# MCU_MCAN0_CFG register map
Vendor: Texas Instruments
Peripheral module from a debugger description file (folder J721S2).
Registers are 32-bit, access not given, reset 0x0 unless marked. A register's access mark holds for its fields unless they carry their own. Offsets are as the file gives them; lines under a group give offsets from that group; [hi:lo] are bit positions; {n}, {i} and the like mark numbered series; 'fields as' and 'values as' point back to an identical list; <NAME> marks a mode.

## MCU_MCAN0_CFG
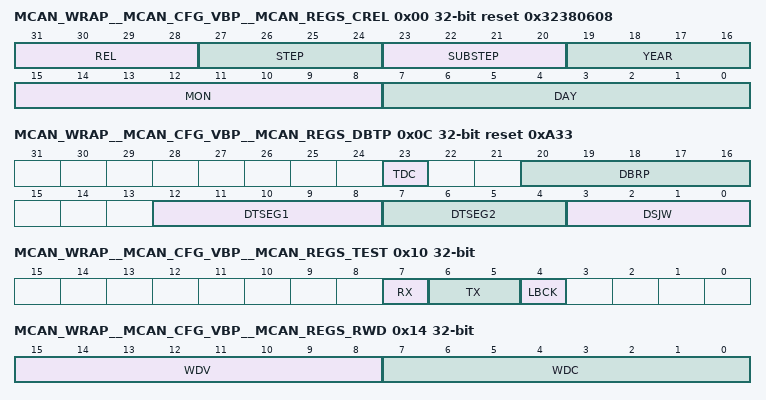
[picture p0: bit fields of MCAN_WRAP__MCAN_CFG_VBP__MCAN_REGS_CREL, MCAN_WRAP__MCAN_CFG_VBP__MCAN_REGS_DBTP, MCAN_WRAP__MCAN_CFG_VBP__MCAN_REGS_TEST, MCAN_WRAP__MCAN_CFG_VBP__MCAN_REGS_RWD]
0x00 MCAN_WRAP__MCAN_CFG_VBP__MCAN_REGS_CREL ro reset 0x32380608 — Release dependent constant (version + date)
  [31:28] REL — Core Release
  [27:24] STEP — Step of Core Release
  [23:20] SUBSTEP — Sub-Step of Core Release
  [19:16] YEAR — Time Stamp Year
  [15:8] MON — Time Stamp Month
  [7:0] DAY — Time Stamp Day
0x04 MCAN_WRAP__MCAN_CFG_VBP__MCAN_REGS_ENDN ro reset 0x87654321 — Constant 0x8765 4321
  [31:0] ETV — Endianess test value
0x08 MCAN_WRAP__MCAN_CFG_VBP__MCAN_REGS_CUST reset not defined — Optional customer-specific register
0x0C MCAN_WRAP__MCAN_CFG_VBP__MCAN_REGS_DBTP rw reset 0xA33 — Configuration of data phase bit timing, transmitter delay compensation enable
  [23] TDC — Transmitter Delay Compensation
  [20:16] DBRP — Data Baud Rate Prescaler
  [12:8] DTSEG1 — Data time segment before sample point
  [7:4] DTSEG2 — Data time segment after sample point
  [3:0] DSJW — Data resynchronization Jump Width
0x10 MCAN_WRAP__MCAN_CFG_VBP__MCAN_REGS_TEST access per field — Test mode selection
  [7] RX ro — Receive Pin
  [6:5] TX rw — Control of Transmit Pin
  [4] LBCK rw — Loop Back Mode
0x14 MCAN_WRAP__MCAN_CFG_VBP__MCAN_REGS_RWD access per field — Monitors the READY output of the Message RAM
  [15:8] WDV ro — Watchdog Value
  [7:0] WDC rw — Watchdog Counter Value
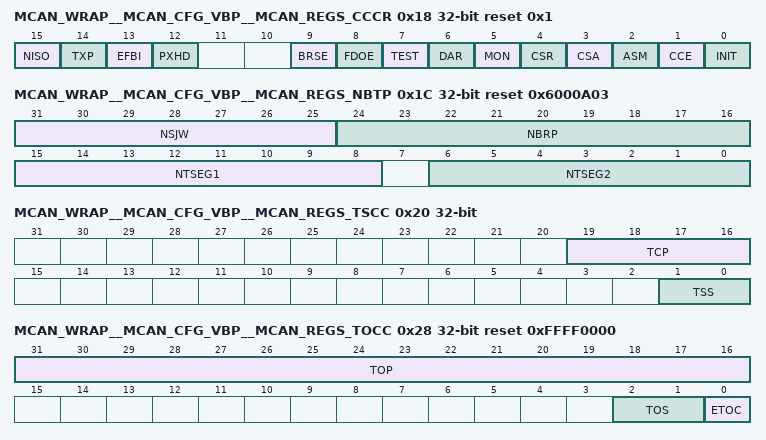
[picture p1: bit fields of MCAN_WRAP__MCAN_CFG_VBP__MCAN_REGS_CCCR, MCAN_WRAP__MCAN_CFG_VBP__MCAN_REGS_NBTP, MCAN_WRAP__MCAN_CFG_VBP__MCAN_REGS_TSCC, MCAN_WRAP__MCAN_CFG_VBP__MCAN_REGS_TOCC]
0x18 MCAN_WRAP__MCAN_CFG_VBP__MCAN_REGS_CCCR access per field reset 0x1 — Operation mode configuration
  [15] NISO rw — Non ISO Operation. 0= CAN FD frame format according to ISO 11898-1:2015. 1= CAN FD frame format according to Bosch CAN FD Specification 1.0
  [14] TXP rw — Transmit Pause
  [13] EFBI rw — Edge Filtering during Bus Integration
  [12] PXHD rw — Protocol Exception Handling Disable
  [9] BRSE rw — Bit Rate Switch Enable
  [8] FDOE rw — FD Operation Enable
  [7] TEST rw — Test Mode enable
  [6] DAR rw — Disable Automatic Retransmission
  [5] MON rw — Bus Monitoring Mode
  [4] CSR rw — Clock Stop Request
  [3] CSA ro — Clock Stop Acknowledge
  [2] ASM rw — Restricted Operation Mode
  [1] CCE rw — Configuration Change Enable
  [0] INIT rw — Initialization
0x1C MCAN_WRAP__MCAN_CFG_VBP__MCAN_REGS_NBTP rw reset 0x6000A03 — Configuration of arbitration phase bit timing
  [31:25] NSJW — Nominal Resynchronization Jump Width
  [24:16] NBRP — Nominal Baud Rate Prescaler
  [15:8] NTSEG1 — Nominal Time segment before sample point
  [6:0] NTSEG2 — Nominal Time segment after sample point
0x20 MCAN_WRAP__MCAN_CFG_VBP__MCAN_REGS_TSCC rw — Timestamp counter prescaler setting, selection of internal/external timestamp vector
  [19:16] TCP — Timestamp Counter Prescaler
  [1:0] TSS — Timestamp Select
0x24 MCAN_WRAP__MCAN_CFG_VBP__MCAN_REGS_TSCV — Read/reset timestamp counter
  [15:0] TSC — Timestamp Counter (access R/WTC)
0x28 MCAN_WRAP__MCAN_CFG_VBP__MCAN_REGS_TOCC rw reset 0xFFFF0000 — Configuration of timeout period, selection of timeout counter operation mode
  [31:16] TOP — Timeout Period
  [2:1] TOS — Timeout Select
  [0] ETOC — Enable Timeout Counter
0x2C MCAN_WRAP__MCAN_CFG_VBP__MCAN_REGS_TOCV reset 0xFFFF — Read/reset timeout counter
  [15:0] TOC — Timeout Counter (access R/WTC)
0x30 MCAN_WRAP__MCAN_CFG_VBP__MCAN_REGS_reserved00 reset not defined — Reserved field
0x34 MCAN_WRAP__MCAN_CFG_VBP__MCAN_REGS_reserved11 reset not defined — Reserved field
0x38 MCAN_WRAP__MCAN_CFG_VBP__MCAN_REGS_reserved22 reset not defined — Reserved field
0x3C MCAN_WRAP__MCAN_CFG_VBP__MCAN_REGS_reserved33 reset not defined — Reserved field
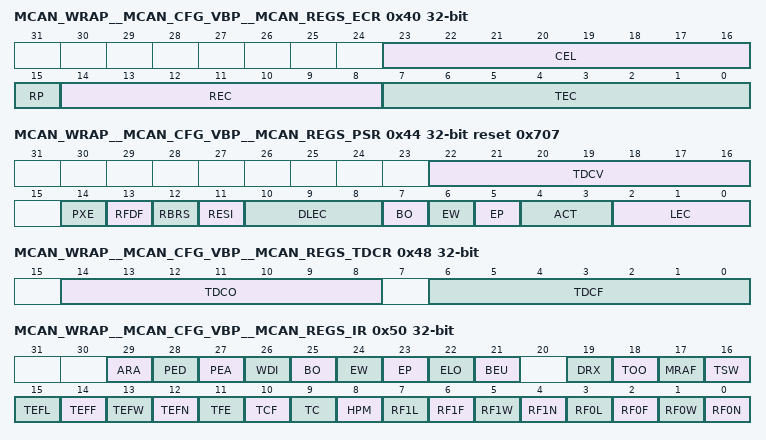
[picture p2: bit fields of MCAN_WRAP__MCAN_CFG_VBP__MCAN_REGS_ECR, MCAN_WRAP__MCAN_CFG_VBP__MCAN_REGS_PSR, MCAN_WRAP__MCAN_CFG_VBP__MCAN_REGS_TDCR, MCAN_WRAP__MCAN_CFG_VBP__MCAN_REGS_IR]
0x40 MCAN_WRAP__MCAN_CFG_VBP__MCAN_REGS_ECR ro — State of Rx/Tx Error Counter, CAN Error Logging
  [23:16] CEL — CAN Error Logging
  [15] RP — Receive Error Passive
  [14:8] REC — Receive Error Counter
  [7:0] TEC — Transmit Error Counter
0x44 MCAN_WRAP__MCAN_CFG_VBP__MCAN_REGS_PSR ro reset 0x707 — CAN protocol controller status, transmitter delay compensation value
  [22:16] TDCV — Transmitter Delay Compensation Value
  [14] PXE — Protocol Exception Event
  [13] RFDF — Received a CAN FD Message
  [12] RBRS — BRS flag of last received CAN FD Message
  [11] RESI — ESI flag of last received CAN FD Message
  [10:8] DLEC — Data Phase Last Error Code
  [7] BO — Bus_Off status
  [6] EW — Warning Status
  [5] EP — Error Passive
  [4:3] ACT — Activity
  [2:0] LEC — Last Error Code
0x48 MCAN_WRAP__MCAN_CFG_VBP__MCAN_REGS_TDCR rw — configuration of transmitter delay compensation offset and filter window length
  [14:8] TDCO — Transmitter Delay Compensation Offset
  [6:0] TDCF — Transmitter Delay Compensation Filter Window Length
0x4C MCAN_WRAP__MCAN_CFG_VBP__MCAN_REGS_reserved44 reset not defined — Reserved field
0x50 MCAN_WRAP__MCAN_CFG_VBP__MCAN_REGS_IR — Interrupt flags
  [29] ARA — Access to Reserved Address (access R/W1TC)
  [28] PED — Protocol Error in data Phase (access R/W1TC)
  [27] PEA — Protocol Error in Arbitration Phase (access R/W1TC)
  [26] WDI — Watchdog Interrupt (access R/W1TC)
  [25] BO — Bus_Off Status (access R/W1TC)
  [24] EW — Warning Status (access R/W1TC)
  [23] EP — Error Passive (access R/W1TC)
  [22] ELO — Error Logging Overflow (access R/W1TC)
  [21] BEU — Bit Error Uncorrected (access R/W1TC)
  [19] DRX — Message stored to Dedicated Rx Buffer (access R/W1TC)
  [18] TOO — Timeout Occurred (access R/W1TC)
  [17] MRAF — Message RAM Access Failure (access R/W1TC)
  [16] TSW — Timestamp Wraparound (access R/W1TC)
  [15] TEFL — Tx Event FIFO Element Lost (access R/W1TC)
  [14] TEFF — Tx Event FIFO Full (access R/W1TC)
  [13] TEFW — Tx Event FIFO Watermark Reached (access R/W1TC)
  [12] TEFN — Tx Event FIFO New Entry (access R/W1TC)
  [11] TFE — Tx FIFO Empty (access R/W1TC)
  [10] TCF — Transmission Cancellation Finished (access R/W1TC)
  [9] TC — Transmission Complete (access R/W1TC)
  [8] HPM — High Priority Message (access R/W1TC)
  [7] RF1L — Rx FIFO 1 Message Lost (access R/W1TC)
  [6] RF1F — Rx FIFO 1 Full (access R/W1TC)
  [5] RF1W — Rx FIFO 1 Watermark Reached (access R/W1TC)
  [4] RF1N — Rx FIFO 1 New Message (access R/W1TC)
  [3] RF0L — Rx FIFO 0 Message Lost (access R/W1TC)
  [2] RF0F — Rx FIFO 0 Full (access R/W1TC)
  [1] RF0W — Rx FIFO 0 Watermark Reached (access R/W1TC)
  [0] RF0N — Rx FIFO 0 New Message (access R/W1TC)
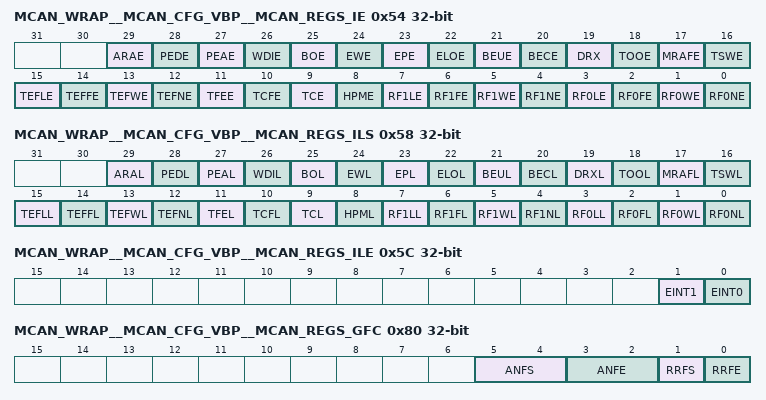
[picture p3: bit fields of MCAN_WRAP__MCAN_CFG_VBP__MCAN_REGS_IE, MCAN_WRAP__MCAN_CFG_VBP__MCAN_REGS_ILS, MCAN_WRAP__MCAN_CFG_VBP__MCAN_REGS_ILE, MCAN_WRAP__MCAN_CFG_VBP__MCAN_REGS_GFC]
0x54 MCAN_WRAP__MCAN_CFG_VBP__MCAN_REGS_IE rw — Interrupt enable/disable
  [29] ARAE — Access to Reserve Address Interrupt Enable
  [28] PEDE — Protocol Error in Data Phase Interrupt Enable
  [27] PEAE — Protocol Error in Arbitration Phase Interrupt Enable
  [26] WDIE — Watchdog Interrupt Enable
  [25] BOE — Bus_Off Status Interrupt Enable
  [24] EWE — Warning Status Interrupt Enable
  [23] EPE — Error Passive Interrupt Enable
  [22] ELOE — Error Logging Overflow Interrupt Enable
  [21] BEUE — Bit Error Uncorrected Interrupt Enable
  [20] BECE — Bit Error Corrected Interrupt Enable
  [19] DRX — Message stored to Dedicated Rx Buffer Interrupt Enable
  [18] TOOE — Timeout Occurred Interrupt Enable
  [17] MRAFE — Message RAM Access Failure Interrupt Enable
  [16] TSWE — Timestamp Wraparound Interrupt Enable
  [15] TEFLE — Tx Event FIFO Event Lost Interrupt Enable
  [14] TEFFE — Tx Event FIFO Full Interrupt Enable
  [13] TEFWE — Tx Event FIFO Watermark Reached Interrupt enable
  [12] TEFNE — Tx Event FIFO New Entry Interrupt Enable
  [11] TFEE — Tx FIFO Empty Interrupt Enable
  [10] TCFE — Transmission Cancellation Finished Interrupt Enable
  [9] TCE — Transmission Completed Interrupt Enable
  [8] HPME — High Priority message Interrupt Enable
  [7] RF1LE — rx FIFO 1 Message Lost Interrupt Enable
  [6] RF1FE — Rx FIFO 1 Full Interrupt Enable
  [5] RF1WE — Rx FIFO 1 Watermark Reached Interrupt Enable
  [4] RF1NE — Rx FIFO 1 New Message Interrupt Enable
  [3] RF0LE — Rx FIFO 0 Message Lost Interrupt Enable
  [2] RF0FE — Rx FIFO 0 Full Interrupt Enable
  [1] RF0WE — Rx FIFO 0 Watermark Reached Interrupt Enable
  [0] RF0NE — Rx FIFO 0 New Message Interrupt Enable
0x58 MCAN_WRAP__MCAN_CFG_VBP__MCAN_REGS_ILS rw — Interrupt line select (m_can_int0 or m_can_int1)
  [29] ARAL — Access to Reserve Address Interrupt Line
  [28] PEDL — Protocol Error in Data Phase Interrupt Line
  [27] PEAL — Protocol Error in Arbitration Phase Interrupt Line
  [26] WDIL — Watchdog Interrupt Line
  [25] BOL — Bus_Off Status Interrupt Line
  [24] EWL — Warning Status Interrupt Line
  [23] EPL — Error Passive Interrupt Line
  [22] ELOL — Error Logging Overflow Interrupt Line
  [21] BEUL — Bit Error Uncorrected Interrupt Line
  [20] BECL — Bit Error Corrected Interrupt Line
  [19] DRXL — Message stored to Dedicated Rx Buffer Interrupt Line
  [18] TOOL — Timeout Occurred Interrupt Line
  [17] MRAFL — Message RAM Access Failure Interrupt Line
  [16] TSWL — Timestamp Wraparound Interrupt Line
  [15] TEFLL — Tx Event FIFO Event Lost Interrupt Line
  [14] TEFFL — Tx Event FIFO Full Interrupt Line
  [13] TEFWL — Tx Event FIFO Watermark Reached Interrupt Line
  [12] TEFNL — Tx Event FIFO New Entry Interrupt Line
  [11] TFEL — Tx FIFO Empty Interrupt Line
  [10] TCFL — Transmission Cancellation Finishied Interrupt Line
  [9] TCL — Transmission Completed Interrupt Line
  [8] HPML — High Priority message Interrupt Line
  [7] RF1LL — rx FIFO 1 Message Lost Interrupt Line
  [6] RF1FL — Rx FIFO 1 Full Interrupt Line
  [5] RF1WL — Rx FIFO 1 Watermark Reached Interrupt Line
  [4] RF1NL — Rx FIFO 1 New Message Interrupt Line
  [3] RF0LL — Rx FIFO 0 Message Lost Interrupt Line
  [2] RF0FL — Rx FIFO 0 Full Interrupt Line
  [1] RF0WL — Rx FIFO 0 Watermark Reached Interrupt Line
  [0] RF0NL — Rx FIFO 0 New Message Interrupt Line
0x5C MCAN_WRAP__MCAN_CFG_VBP__MCAN_REGS_ILE rw — Enable/disable interrupt lines m_can_int0 / m_can_int1
  [1] EINT1 — Enable Interrupt Line 1
  [0] EINT0 — Enable Interrupt Line 0
0x60 MCAN_WRAP__MCAN_CFG_VBP__MCAN_REGS_reserved55 reset not defined — Reserved field
0x64 MCAN_WRAP__MCAN_CFG_VBP__MCAN_REGS_reserved66 reset not defined — Reserved field
0x68 MCAN_WRAP__MCAN_CFG_VBP__MCAN_REGS_reserved77 reset not defined — Reserved field
0x6C MCAN_WRAP__MCAN_CFG_VBP__MCAN_REGS_reserved88 reset not defined — Reserved field
0x70 MCAN_WRAP__MCAN_CFG_VBP__MCAN_REGS_reserved99 reset not defined — Reserved field
0x74 MCAN_WRAP__MCAN_CFG_VBP__MCAN_REGS_reserved1010 reset not defined — Reserved field
0x78 MCAN_WRAP__MCAN_CFG_VBP__MCAN_REGS_reserved1111 reset not defined — Reserved field
0x7C MCAN_WRAP__MCAN_CFG_VBP__MCAN_REGS_reserved1212 reset not defined — Reserved field
0x80 MCAN_WRAP__MCAN_CFG_VBP__MCAN_REGS_GFC rw — Handling of non-matching frames and remote frames
  [5:4] ANFS — Accept Non-matching Frames Standard
  [3:2] ANFE — Accept Non-matching Frames Extended
  [1] RRFS — reject Remote Frames Standard
  [0] RRFE — reject Remote Frames Extended
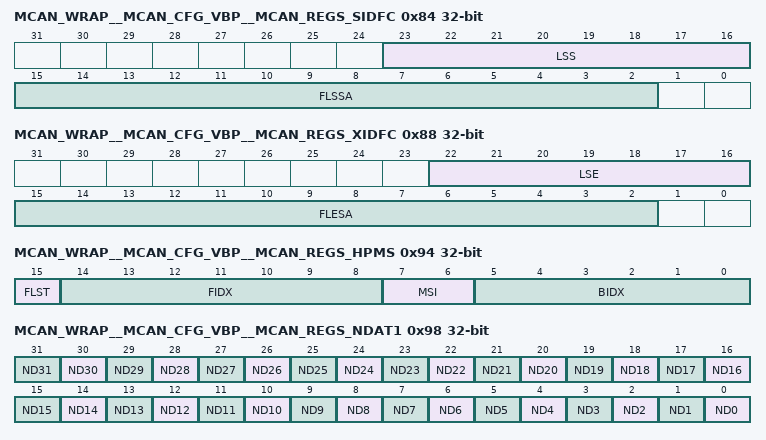
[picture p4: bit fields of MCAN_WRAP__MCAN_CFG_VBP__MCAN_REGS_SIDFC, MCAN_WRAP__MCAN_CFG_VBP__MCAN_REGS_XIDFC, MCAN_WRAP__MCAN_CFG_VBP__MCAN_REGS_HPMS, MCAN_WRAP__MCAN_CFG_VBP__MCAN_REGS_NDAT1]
0x84 MCAN_WRAP__MCAN_CFG_VBP__MCAN_REGS_SIDFC rw — Number of filter elements, pointer to start of filter list
  [23:16] LSS — List Size Standard
  [15:2] FLSSA — Filter List Standard Start Address
0x88 MCAN_WRAP__MCAN_CFG_VBP__MCAN_REGS_XIDFC rw — Number of filter elements, pointer to start of filter list
  [22:16] LSE — List Size Extended
  [15:2] FLESA — Filter List Extended Start Address
0x8C MCAN_WRAP__MCAN_CFG_VBP__MCAN_REGS_reserved1313 reset not defined — Reserved field
0x90 MCAN_WRAP__MCAN_CFG_VBP__MCAN_REGS_XIDAM rw reset 0x1FFFFFFF — 29-bit logical AND mask for J1939
  [28:0] EIDM — Extended ID Mask
0x94 MCAN_WRAP__MCAN_CFG_VBP__MCAN_REGS_HPMS ro — Status monitoring of incoming high priority messages
  [15] FLST — Filter List
  [14:8] FIDX — Filter Index
  [7:6] MSI — Message Storage Indicator
  [5:0] BIDX — Buffer Index
0x98 MCAN_WRAP__MCAN_CFG_VBP__MCAN_REGS_NDAT1 — NewDat flags of dedicated Rx buffers 0-31
  [n] ND{n} (n=0..31) — New Data (access R/W1TC)
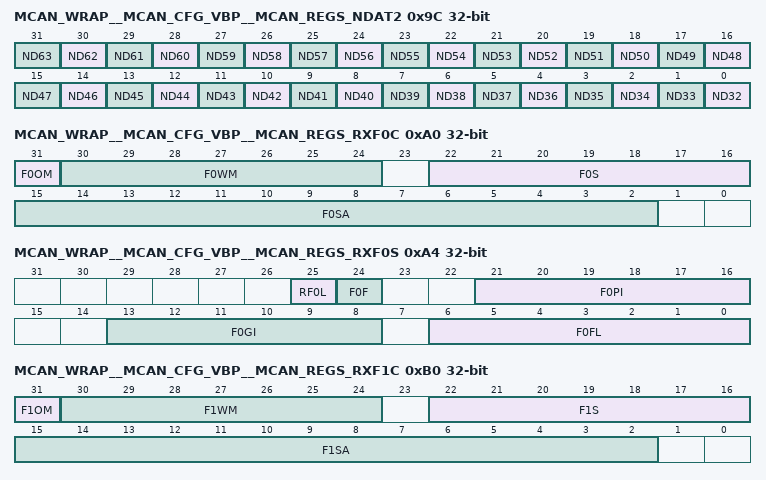
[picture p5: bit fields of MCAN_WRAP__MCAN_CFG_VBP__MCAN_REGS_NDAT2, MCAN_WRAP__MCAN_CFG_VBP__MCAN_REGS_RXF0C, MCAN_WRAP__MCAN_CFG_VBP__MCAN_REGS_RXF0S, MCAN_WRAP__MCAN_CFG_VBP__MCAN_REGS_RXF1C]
0x9C MCAN_WRAP__MCAN_CFG_VBP__MCAN_REGS_NDAT2 — NewDat flags of dedicated Rx buffers 32-63
  [n-32] ND{n} (n=32..63) — New Data (access R/W1TC)
0xA0 MCAN_WRAP__MCAN_CFG_VBP__MCAN_REGS_RXF0C rw — FIFO 0 operation mode, watermark, size and start address
  [31] F0OM — Rx FIFO 0 Operation Mode
  [30:24] F0WM — Rx FIFO 0 Watermark
  [22:16] F0S — Rx FIFO 0 Size
  [15:2] F0SA — Rx FIFO 0 Start Address
0xA4 MCAN_WRAP__MCAN_CFG_VBP__MCAN_REGS_RXF0S ro — FIFO 0 message lost/full indication, put index, get index and fill level
  [25] RF0L — Rx FIFO 0 Message Lost
  [24] F0F — Rx FIFO 0 Full
  [21:16] F0PI — Rx FIFO 0 Put Index
  [13:8] F0GI — Rx FIFO 0 Get Index
  [6:0] F0FL — Rx FIFO 0 Fill Level
0xA8 MCAN_WRAP__MCAN_CFG_VBP__MCAN_REGS_RXF0A rw — FIFO 0 acknowledge last index of read buffers, updates get index and fill level
  [5:0] F0AI — Rx FIFO 0 Acknowledge Index
0xAC MCAN_WRAP__MCAN_CFG_VBP__MCAN_REGS_RXBC rw — Start address of Rx buffer section
  [15:2] RBSA — Rx Buffer Start Address
0xB0 MCAN_WRAP__MCAN_CFG_VBP__MCAN_REGS_RXF1C rw — FIFO 1 operation mode, watermark, size and start address
  [31] F1OM — Rx FIFO 1 Operation Mode
  [30:24] F1WM — Rx FIFO 1 Watermark
  [22:16] F1S — Rx FIFO 1 Size
  [15:2] F1SA — Rx FIFO 1 Start Address
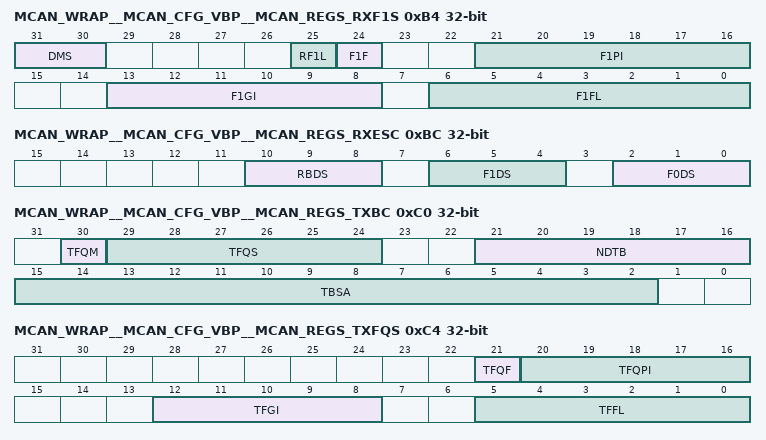
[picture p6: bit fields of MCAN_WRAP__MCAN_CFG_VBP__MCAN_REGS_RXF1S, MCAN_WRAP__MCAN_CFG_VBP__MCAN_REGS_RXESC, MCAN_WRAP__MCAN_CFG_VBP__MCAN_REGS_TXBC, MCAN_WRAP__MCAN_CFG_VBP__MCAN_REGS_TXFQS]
0xB4 MCAN_WRAP__MCAN_CFG_VBP__MCAN_REGS_RXF1S ro — FIFO 1 message lost/full indication, put index, get index and fill level
  [31:30] DMS — Debug Message Status
  [25] RF1L — Rx FIFO 1 Message Lost
  [24] F1F — Rx FIFO 1 Full
  [21:16] F1PI — Rx FIFO 1 Put Index
  [13:8] F1GI — Rx FIFO 1 Get Index
  [6:0] F1FL — Rx FIFO 1 Fill Level
0xB8 MCAN_WRAP__MCAN_CFG_VBP__MCAN_REGS_RXF1A rw — FIFO 1 acknowledge last index of read buffers, updates get index and fill level
  [5:0] F1AI — Rx FIFO 1 Acknowledge Index
0xBC MCAN_WRAP__MCAN_CFG_VBP__MCAN_REGS_RXESC rw — Configure data field size for storage of accepted frames
  [10:8] RBDS — Rx Buffer data Field Size
  [6:4] F1DS — Rx FIFO 1 Data Field Size
  [2:0] F0DS — Rx FIFO 0 Data Field Size
0xC0 MCAN_WRAP__MCAN_CFG_VBP__MCAN_REGS_TXBC rw — Configure Tx FIFO/Queue mode, Tx FIFO/Queue size, number of dedicated Tx buffers, Tx buffer start address
  [30] TFQM — Tx FIFO/Queue Mode
  [29:24] TFQS — Transmit FIFO/Queue Size
  [21:16] NDTB — Number of Dedicated Transmit Buffers
  [15:2] TBSA — Tx Buffers Start Address
0xC4 MCAN_WRAP__MCAN_CFG_VBP__MCAN_REGS_TXFQS ro — Tx FIFO/Queue full indication and put index, Tx FIFO get index and fill level
  [21] TFQF — Tx FIFO/Queue Full
  [20:16] TFQPI — Tx FIFO/Queue Put Index
  [12:8] TFGI — Tx Queue Get Index
  [5:0] TFFL — Tx FIFO Free Level
0xC8 MCAN_WRAP__MCAN_CFG_VBP__MCAN_REGS_TXESC rw — Configure data field size for frame transmission
  [2:0] TBDS — Tx Buffer Data Field Size
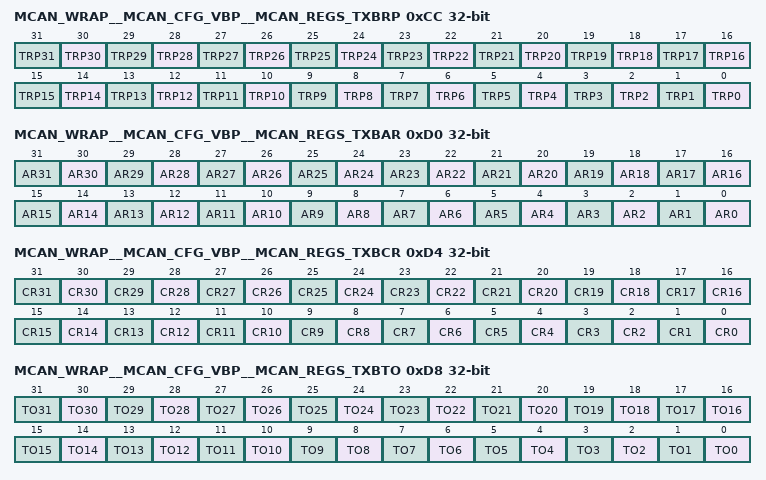
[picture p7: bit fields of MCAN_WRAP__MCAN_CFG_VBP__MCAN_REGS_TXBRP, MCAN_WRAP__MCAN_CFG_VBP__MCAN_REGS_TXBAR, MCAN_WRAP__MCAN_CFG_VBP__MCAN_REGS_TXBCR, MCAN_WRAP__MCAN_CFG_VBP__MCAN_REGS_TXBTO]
0xCC MCAN_WRAP__MCAN_CFG_VBP__MCAN_REGS_TXBRP ro — Tx buffers with pending transmission request
  [n] TRP{n} (n=0..31) — Transmission Request Pending
0xD0 MCAN_WRAP__MCAN_CFG_VBP__MCAN_REGS_TXBAR — Add transmission requests
  [n] AR{n} (n=0..31) — Add request (access R/W1TC)
0xD4 MCAN_WRAP__MCAN_CFG_VBP__MCAN_REGS_TXBCR — Request cancellation of pending transmissions
  [n] CR{n} (n=0..31) — Cancellation Request (access R/W1TC)
0xD8 MCAN_WRAP__MCAN_CFG_VBP__MCAN_REGS_TXBTO ro — Signals successful transmissions, set when corresponding TXBRP flag is cleared
  [n] TO{n} (n=0..31) — Transmission Occurred
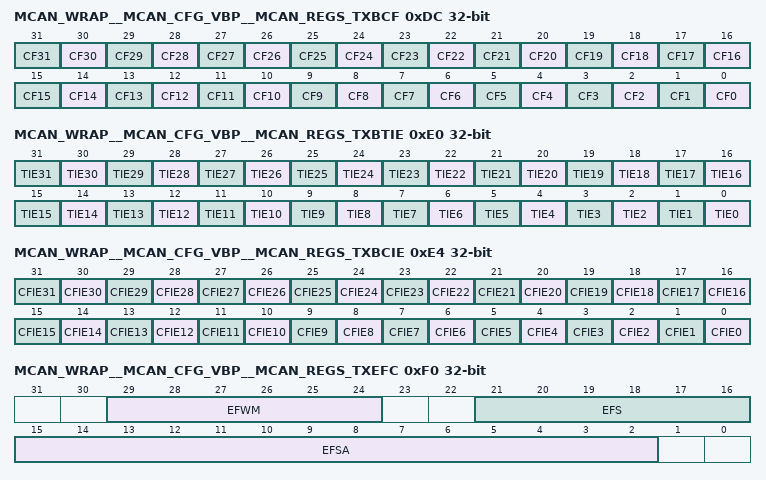
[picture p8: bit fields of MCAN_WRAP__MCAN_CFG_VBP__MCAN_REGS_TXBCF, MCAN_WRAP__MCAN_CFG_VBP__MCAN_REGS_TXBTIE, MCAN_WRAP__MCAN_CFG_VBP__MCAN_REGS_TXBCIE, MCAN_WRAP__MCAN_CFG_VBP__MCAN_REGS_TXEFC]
0xDC MCAN_WRAP__MCAN_CFG_VBP__MCAN_REGS_TXBCF ro — Signals successful transmit cancellation, set when corresponding TXBRP flag is cleared after cancellation request
  [n] CF{n} (n=0..31) — Cancellation Finished
0xE0 MCAN_WRAP__MCAN_CFG_VBP__MCAN_REGS_TXBTIE rw — Enable transmit interrupts for selected Tx buffers
  [n] TIE{n} (n=0..31) — Transmission Interrupt Enable
0xE4 MCAN_WRAP__MCAN_CFG_VBP__MCAN_REGS_TXBCIE rw — Enable cancellation finished interrupts for selected Tx buffers
  [n] CFIE{n} (n=0..31) — Cancellation Finished Interrupt Enable
0xE8 MCAN_WRAP__MCAN_CFG_VBP__MCAN_REGS_reserved1414 reset not defined — Reserved Field
0xEC MCAN_WRAP__MCAN_CFG_VBP__MCAN_REGS_reserved1515 reset not defined — Reserved Field
0xF0 MCAN_WRAP__MCAN_CFG_VBP__MCAN_REGS_TXEFC rw — Tx event FIFO watermark, size and start address
  [29:24] EFWM — Event FIFO Watermark
  [21:16] EFS — Event FIFO Size
  [15:2] EFSA — Event FIFO Start Address
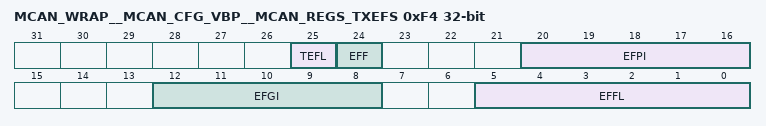
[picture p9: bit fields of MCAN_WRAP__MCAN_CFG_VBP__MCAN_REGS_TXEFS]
0xF4 MCAN_WRAP__MCAN_CFG_VBP__MCAN_REGS_TXEFS ro — Tx event FIFO element lost/full indication, put index, get index, and fill level
  [25] TEFL — Tx Event FIFO Element Lost
  [24] EFF — Event FIFO Full
  [20:16] EFPI — Event FIFO Put Index
  [12:8] EFGI — Event FIFO Get Index
  [5:0] EFFL — Event FIFO Fill Level
0xF8 MCAN_WRAP__MCAN_CFG_VBP__MCAN_REGS_TXEFA rw — Tx event FIFO acknowledge last index of read elements, updates get index and fill level
  [4:0] EFAI — Event FIFO Acknowledge Index
0xFC MCAN_WRAP__MCAN_CFG_VBP__MCAN_REGS_reserved1616 reset not defined — Reserved Field
0x100 MCAN_WRAP__MCAN_CFG_VBP__MCAN_REGS_ReservUpper256 reset not defined — Reserved Field
